# STMP3770 register map
Vendor: Freescale Semiconductor (NXP); Series: STMP37xx; File version: 1.0
CPU: other r0p0, little endian, no MPU, no FPU, 2 interrupt priority bits
Registers are 32-bit, read-write, reset 0x0 unless marked. A register's access mark holds for its fields unless they carry their own. Offsets are from the block's base; [hi:lo] are bit positions; {n}, {i} and the like mark numbered series.

## DCP — 数据协处理器(DCP,硬件 AES/SHA 加解密与哈希,支持内存拷贝/校验)
Base 0x80028000
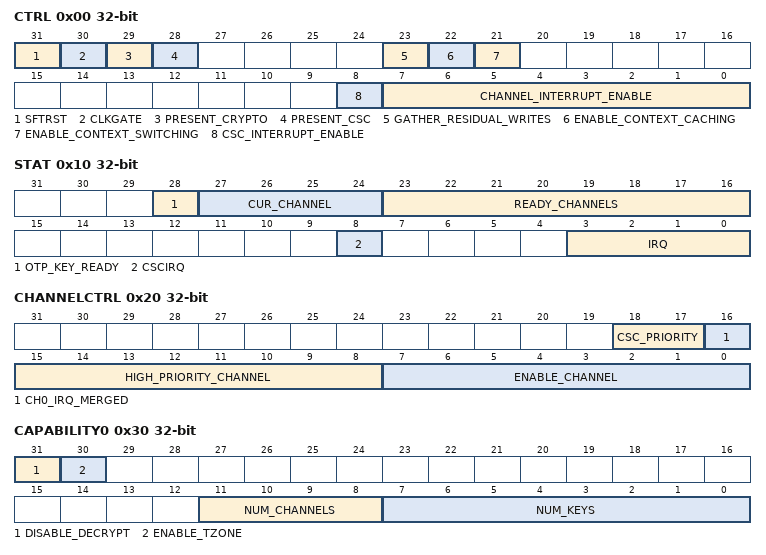
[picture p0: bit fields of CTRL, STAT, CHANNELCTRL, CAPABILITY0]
0x00 CTRL — DCP Control Register 0
  [31] SFTRST — Clear to 0 to enable normal DCP operation. Set to 1 (default) to disable clocking and hold in reset (lowest power) state.
  [30] CLKGATE — Must be cleared to 0 for normal operation. When set to 1, gates off the clocks to the block.
  [29] PRESENT_CRYPTO — Indicates whether the crypto (cipher/hash) functions are present. Present=0x1, Absent=0x0.
    1=Present; 0=Absent
  [28] PRESENT_CSC — Indicates whether the CSC function is present. Present=0x1, Absent=0x0.
    1=Present; 0=Absent
  [23] GATHER_RESIDUAL_WRITES — Enable ragged writes to unaligned buffers to be gathered between multiple write operations. Improves performance.
  [22] ENABLE_CONTEXT_CACHING — Enable caching of contexts between operations. If only one channel used for encryption/hashing, context not reloaded if channel was last used.
  [21] ENABLE_CONTEXT_SWITCHING — Enable automatic context switching for channels. Set if more than one channel does hashing/cipher requiring context save (e.g. CBC mode).
  [8] CSC_INTERRUPT_ENABLE — Interrupt enable bit for the CSC. Combined with channels 1-3 interrupts to form dcp_irq.
  [7:0] CHANNEL_INTERRUPT_ENABLE — Per-channel interrupt enable. CH0=0x01, CH1=0x02, CH2=0x04, CH3=0x08. CH0 routed to dcp_vmi_irq, others to dcp_irq.
    1=CH0; 2=CH1; 4=CH2; 8=CH3
0x10 STAT — DCP Status Register
  [28] OTP_KEY_READY — When set, indicates the OTP key has been shifted from the fuse block and is ready for use.
  [27:24] CUR_CHANNEL — Current (active) channel encoded. None=0x0, CH0=0x1, CH1=0x2, CH2=0x3, CH3=0x4, CSC=0x8.
    0=None; {v}=CH{v-1} (v=1..4); 8=CSC
  [23:16] READY_CHANNELS — Indicates which channels are ready to proceed with a transfer. One-hot per channel.
    1=CH0; 2=CH1; 4=CH2; 8=CH3
  [8] CSCIRQ — Indicates CSC has a pending interrupt request. Appears on dcp_irq line.
  [3:0] IRQ — Indicates channels with pending interrupts. CH0 on dcp_vmi_irq, others on dcp_irq.
0x20 CHANNELCTRL — DCP Channel Control Register
  [18:17] CSC_PRIORITY — Sets CSC priority: HIGH=0x3, MED=0x2, LOW=0x1, BACKGROUND=0x0.
    3=HIGH; 2=MED; 1=LOW; 0=BACKGROUND
  [16] CH0_IRQ_MERGED — 通道0中断合并，置位时CH0中断并入共享dcp_irq。
  [15:8] HIGH_PRIORITY_CHANNEL — Setting a bit marks the channel for high-priority arbitration. Round-robin among them. CH0=0x01, CH1=0x02, CH2=0x04, CH3=0x08.
    1=CH0; 2=CH1; 4=CH2; 8=CH3
  [7:0] ENABLE_CHANNEL — Setting a bit enables the DMA channel. CH0=0x01, CH1=0x02, CH2=0x04, CH3=0x08.
    1=CH0; 2=CH1; 4=CH2; 8=CH3
0x30 CAPABILITY0 — DCP Capability 0 Register
  [31] DISABLE_DECRYPT — 解密禁用标志。
  [30] ENABLE_TZONE — 信任区使能标志。
  [11:8] NUM_CHANNELS — Encoded value indicating the number of channels implemented.
  [7:0] NUM_KEYS — Encoded value indicating the number of key storage locations.
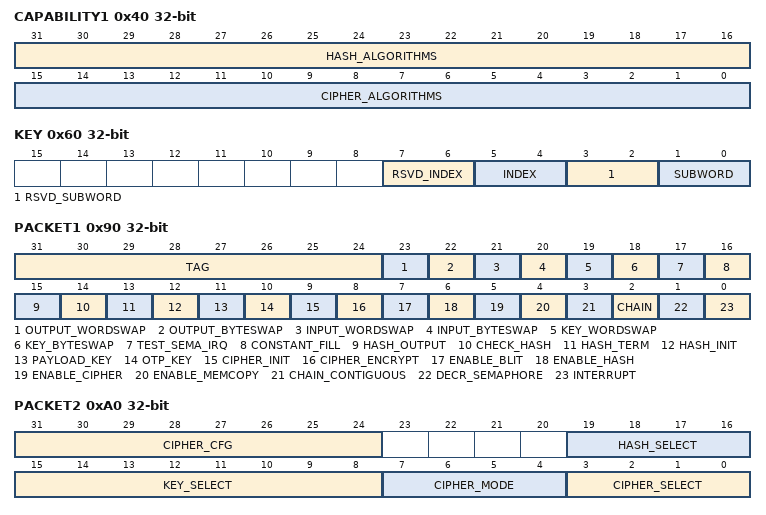
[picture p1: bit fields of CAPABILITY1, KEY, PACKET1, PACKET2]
0x40 CAPABILITY1 — DCP Capability 1 Register
  [31:16] HASH_ALGORITHMS — One-hot field indicating hashing algorithms available. SHA1=0x0001, CRC32=0x0002.
    1=SHA1; 2=CRC32
  [15:0] CIPHER_ALGORITHMS — One-hot field indicating cipher algorithms available. AES128=0x0001.
    1=AES128
0x50 CONTEXT — DCP Context Buffer Pointer
  [31:0] ADDR — Context pointer address. Should be in system RAM and word-aligned for optimal performance.
0x60 KEY — DCP Key Index
  [7:6] RSVD_INDEX — 保留关键字索引导。
  [5:4] INDEX — Key index pointer. Valid indices are 0-[number_keys].
  [3:2] RSVD_SUBWORD — 保留关键字子字域。
  [1:0] SUBWORD — Key subword pointer. Valid indices 0-3. Auto-increments after each key data write.
0x70 KEYDATA — DCP Key Data
  [31:0] DATA — Word 0 data for key. This is the least-significant word.
0x80 PACKET0 — DCP Work Packet 0 Status Register
  [31:0] ADDR — Next Pointer Register.
0x90 PACKET1 — DCP Work Packet 1 Status Register
  [31:24] TAG — Packet Tag.
  [23] OUTPUT_WORDSWAP — Reflects whether the DCP engine word-swaps output data (big-endian).
  [22] OUTPUT_BYTESWAP — Reflects whether the DCP engine byte-swaps output data (big-endian).
  [21] INPUT_WORDSWAP — Reflects whether the DCP engine word-swaps input data (big-endian).
  [20] INPUT_BYTESWAP — Reflects whether the DCP engine byte-swaps input data (big-endian).
  [19] KEY_WORDSWAP — Reflects whether the DCP engine swaps key words (big-endian key).
  [18] KEY_BYTESWAP — Reflects whether the DCP engine swaps key bytes (big-endian key).
  [17] TEST_SEMA_IRQ — Used to test the channel semaphore transition to 0. FOR TEST USE ONLY!
  [16] CONSTANT_FILL — When set (MEMCOPY/BLIT modes), DCP fills destination buffer with value from Source Address field.
  [15] HASH_OUTPUT — Controls whether input or output data is hashed. INPUT=0x00, OUTPUT=0x01.
    0=INPUT; 1=OUTPUT
  [14] CHECK_HASH — Reflects whether the calculated hash should be compared against payload hash.
  [13] HASH_TERM — Reflects whether current hashing block is the final block; hash padding applied by hardware.
  [12] HASH_INIT — Reflects whether current hashing block is initial block; hash registers initialized before operation.
  [11] PAYLOAD_KEY — When set, payload contains the key. Takes precedence over OTP_KEY.
  [10] OTP_KEY — Reflects whether a hardware-based key should be used. KEY_SELECT selects key.
  [9] CIPHER_INIT — Reflects whether the cipher block should load IV from payload.
  [8] CIPHER_ENCRYPT — Indicates encryption or decryption. ENCRYPT=0x01, DECRYPT=0x00.
    1=ENCRYPT; 0=DECRYPT
  [7] ENABLE_BLIT — Reflects whether DCP performs blit. BUFFER_SIZE treated as two 16-bit X-Y extents.
  [6] ENABLE_HASH — Reflects whether hashing function is enabled for this operation.
  [5] ENABLE_CIPHER — Reflects whether cipher function is enabled for this operation.
  [4] ENABLE_MEMCOPY — Reflects whether memcopy function is enabled for this operation.
  [3] CHAIN_CONTIGUOUS — Reflects whether next packet's address is located following this packet's payload.
  [2] CHAIN — Reflects whether next command pointer should be loaded into channel's descriptor pointer.
  [1] DECR_SEMAPHORE — Reflects whether channel semaphore decremented at end of current operation.
  [0] INTERRUPT — Reflects whether channel should issue interrupt upon packet completion.
0xA0 PACKET2 — DCP Work Packet 2 Status Register
  [31:24] CIPHER_CFG — Cipher configuration bits. Optional configuration required for ciphers.
  [19:16] HASH_SELECT — Hash Selection. SHA1=0x00, CRC32=0x01.
    0=SHA1; 1=CRC32
  [15:8] KEY_SELECT — Key Selection reflecting the key index for cipher operation.
  [7:4] CIPHER_MODE — Cipher Mode Selection. ECB=0x00, CBC=0x01.
    0=ECB; 1=CBC
  [3:0] CIPHER_SELECT — Cipher Selection Field. AES128=0x00.
    0=AES128
0xB0 PACKET3 — DCP Work Packet 3 Status Register
  [31:0] ADDR — Source Buffer Address Pointer. Working value, updates as operation proceeds.
0xC0 PACKET4 — DCP Work Packet 4 Status Register
  [31:0] ADDR — Destination Buffer Address Pointer. Working value, updates as operation proceeds.
0xD0 PACKET5 — DCP Work Packet 5 Status Register
  [31:0] COUNT — Byte Count register. Working value, updates as operation proceeds.
0xE0 PACKET6 — DCP Work Packet 6 Status Register
  [31:0] ADDR — Payload pointer for the current control packet.
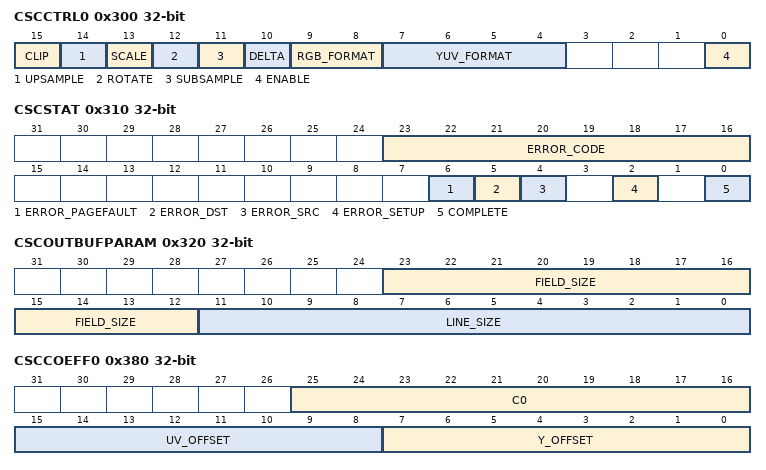
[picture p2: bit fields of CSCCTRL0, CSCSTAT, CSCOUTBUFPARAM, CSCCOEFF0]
0x300 CSCCTRL0 — Color Space Conversion Control Register 0
  [15] CLIP — CSC输出裁剪使能。
  [14] UPSAMPLE — Upsample subsampled chroma at luma locations before color conversion. Smooths horizontal color transitions.
  [13] SCALE — Output image should be scaled. CSCXSCALE/CSCYSCALE registers must be programmed.
  [12] ROTATE — Output image should be rotated (clockwise 90 degrees with horizontal flip).
  [11] SUBSAMPLE — Pixel subsampling. Only enable when DELTA bit is set.
  [10] DELTA — Framebuffer color ordering for delta pixel config. For 24-bit RGB only.
  [9:8] RGB_FORMAT — Target RGB framebuffer format. RGB16_565=0x0, RGB24=0x2, YUV422I=0x3.
    0=RGB16_565; 1=YCbCrI; 2=RGB24; 3=YUV422I
  [7:4] YUV_FORMAT — YUV Input Buffer format. YUV420=0x0, YUV422=0x2.
    0=YUV420; 2=YUV422
  [0] ENABLE — Enables color-space conversion with specified parameters.
0x310 CSCSTAT — Color Space Conversion Status Register
  [23:16] ERROR_CODE — Error codes: LUMA0_FETCH=0x01, LUMA1_FETCH=0x02, CHROMA_U_FETCH=0x03, CHROMA_V_FETCH=0x04.
    1=LUMA0_FETCH_ERROR_Y0; 2=LUMA1_FETCH_ERROR_Y1; 3=CHROMA_FETCH_ERROR_U; 4=CHROMA_FETCH_ERROR_V
  [6] ERROR_PAGEFAULT — CSC页错误状态。
  [5] ERROR_DST — Bus error when writing output RGB buffer. CSC terminates.
  [4] ERROR_SRC — Bus error when reading source buffer. CSC terminates.
  [2] ERROR_SETUP — Invalid programming configuration detected.
  [0] COMPLETE — When set, indicates the CSC has completed its operation.
0x320 CSCOUTBUFPARAM — Color Space Conversion Output Buffer Parameters
  [23:12] FIELD_SIZE — Field size as number of lines (vertical height) for unscaled images.
  [11:0] LINE_SIZE — Line size in horizontal pixels (horizontal width of display).
0x330 CSCINBUFPARAM — Color Space Conversion Input Buffer Parameters
  [11:0] LINE_SIZE — Line size in horizontal pixels (horizontal width of display).
0x340 CSCRGB — Color Space RGB Frame Buffer Pointer
  [31:0] ADDR — Current address pointer for output frame buffer. Working register. MUST be word-aligned.
0x350 CSCLUMA — Color Space Luma (Y) Buffer Pointer
  [31:0] ADDR — Current address pointer for input luminance (Y) buffer. Working register. MUST be word-aligned.
0x360 CSCCHROMAU — Color Space Chroma (U/Cb) Buffer Pointer
  [31:0] ADDR — Current address pointer for input chrominance (U/Cb) buffer. Working register. MUST be word-aligned.
0x370 CSCCHROMAV — Color Space Chroma (V/Cr) Buffer Pointer
  [31:0] ADDR — Current address pointer for input chrominance (V/Cr) buffer. Working register. MUST be word-aligned.
0x380 CSCCOEFF0 — Color Space Conversion Coefficient Register 0
  [25:16] C0 — Y multiplier coefficient.
  [15:8] UV_OFFSET — Phase offset for UV data (typically 128/0x80 for -0.5 to 0.5 range).
  [7:0] Y_OFFSET — Amplitude offset in Y data. YUV=0, CbCr=16 (0x10).
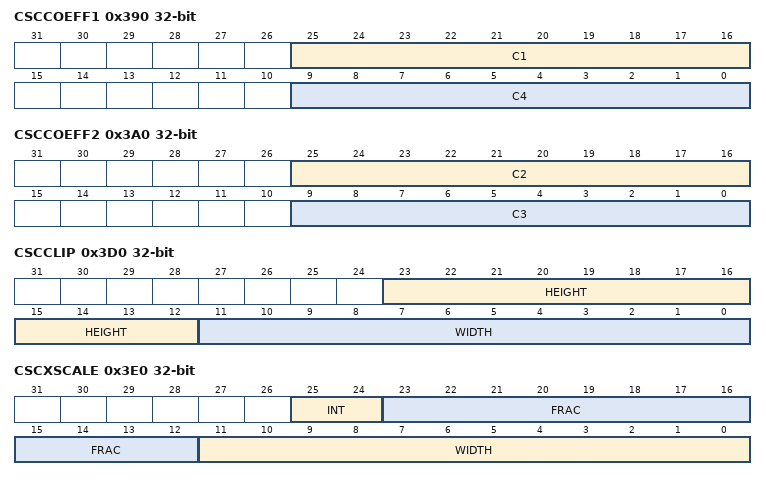
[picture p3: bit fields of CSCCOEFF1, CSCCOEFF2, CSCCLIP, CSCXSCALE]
0x390 CSCCOEFF1 — Color Space Conversion Coefficient Register 1
  [25:16] C1 — Red Cr multiplier coefficient.
  [9:0] C4 — Blue Cb multiplier coefficient.
0x3A0 CSCCOEFF2 — Color Space Conversion Coefficient Register 2
  [25:16] C2 — Green Cr multiplier coefficient.
  [9:0] C3 — Green Cb multiplier coefficient.
0x3D0 CSCCLIP — Color Space Conversion Clipping Register
  [23:12] HEIGHT — CSC裁剪高度。
  [11:0] WIDTH — CSC裁剪宽度。
0x3E0 CSCXSCALE — Color Space Conversion X-Scaling Register
  [25:24] INT — Integer coefficient = source_width/target_width. Upscaling=0, downscaling=1 or 2.
  [23:12] FRAC — Fractional coefficient = source_width % target_width.
  [11:0] WIDTH — Scaled video width.
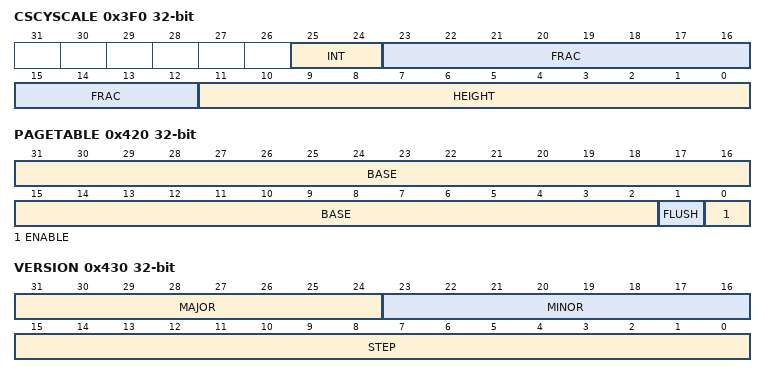
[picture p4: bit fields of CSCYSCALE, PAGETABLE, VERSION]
0x3F0 CSCYSCALE — Color Space Conversion Y-Scaling Register
  [25:24] INT — Integer coefficient = source_height/target_height. Upscaling=0, downscaling=1 or 2.
  [23:12] FRAC — Fractional coefficient = source_height % target_height.
  [11:0] HEIGHT — Scaled video height.
0x400 DBGSELECT — DCP Debug Select Register
  [7:0] INDEX — Selects debug value via debug data register. CONTROL=0x01, OTPKEY0-3=0x10-0x13.
    1=CONTROL; {v}=OTPKEY{v-16} (v=16..19)
0x410 DBGDATA — DCP Debug Data Register
  [31:0] DATA — Debug Data.
0x420 PAGETABLE — DCP Page Table Register
  [31:2] BASE — 页表基地址指针。
  [1] FLUSH — 页表刷新，写1刷新DCP页表缓存。
  [0] ENABLE — 使能控制位，写1使能功能，写0禁用。
0x430 VERSION ro — DCP Version Register
  [31:24] MAJOR — Fixed read-only value reflecting the MAJOR version of the design implementation.
  [23:16] MINOR — Fixed read-only value reflecting the MINOR version of the design implementation.
  [15:0] STEP — Fixed read-only value reflecting the stepping version of the design implementation.
